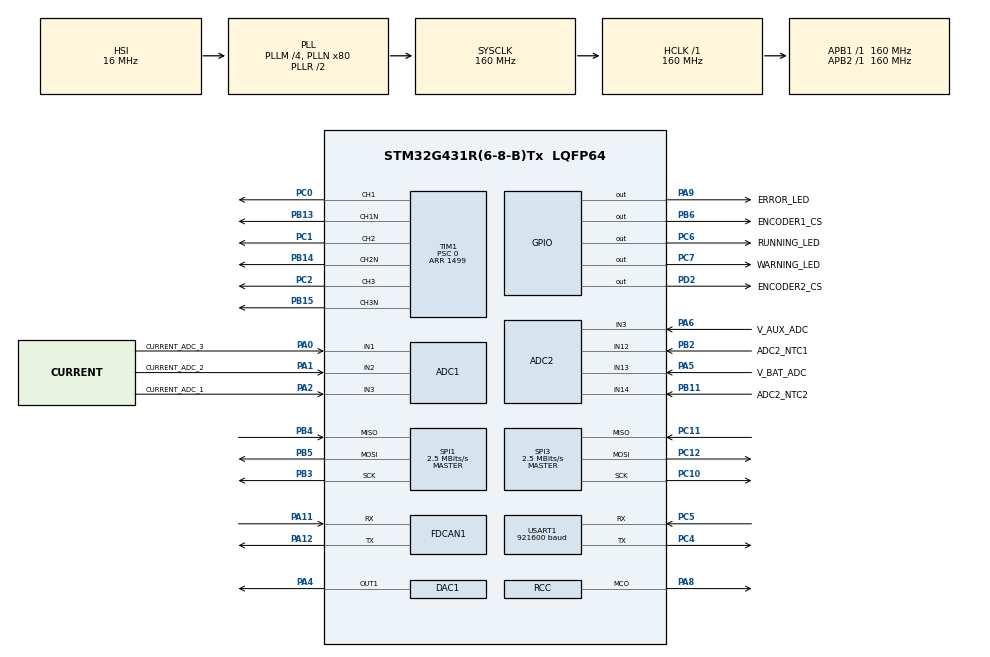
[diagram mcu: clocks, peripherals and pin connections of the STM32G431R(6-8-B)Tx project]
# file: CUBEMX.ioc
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ADC1.Channel-0\#ChannelRegularConversion=ADC_CHANNEL_1
ADC1.Channel-1\#ChannelRegularConversion=ADC_CHANNEL_2
ADC1.Channel-2\#ChannelRegularConversion=ADC_CHANNEL_3
ADC1.Channel-3\#ChannelRegularConversion=ADC_CHANNEL_VREFINT
ADC1.ClockPrescaler=ADC_CLOCK_SYNC_PCLK_DIV4
ADC1.ContinuousConvMode=ENABLE
ADC1.DMAContinuousRequests=ENABLE
ADC1.EOCSelection=ADC_EOC_SEQ_CONV
ADC1.NbrOfConversion=4
ADC1.NbrOfConversionFlag=1
ADC1.OffsetNumber-0\#ChannelRegularConversion=ADC_OFFSET_NONE
ADC1.OffsetNumber-1\#ChannelRegularConversion=ADC_OFFSET_NONE
ADC1.OffsetNumber-2\#ChannelRegularConversion=ADC_OFFSET_NONE
ADC1.OffsetNumber-3\#ChannelRegularConversion=ADC_OFFSET_NONE
ADC1.Overrun=ADC_OVR_DATA_OVERWRITTEN
ADC1.OversamplingMode=ENABLE
ADC1.Rank-0\#ChannelRegularConversion=1
ADC1.Rank-1\#ChannelRegularConversion=2
ADC1.Rank-2\#ChannelRegularConversion=3
ADC1.Rank-3\#ChannelRegularConversion=4
ADC1.Ratio=ADC_OVERSAMPLING_RATIO_16
ADC1.SamplingTime-0\#ChannelRegularConversion=ADC_SAMPLETIME_24CYCLES_5
ADC1.SamplingTime-1\#ChannelRegularConversion=ADC_SAMPLETIME_24CYCLES_5
ADC1.SamplingTime-2\#ChannelRegularConversion=ADC_SAMPLETIME_24CYCLES_5
ADC1.SamplingTime-3\#ChannelRegularConversion=ADC_SAMPLETIME_24CYCLES_5
ADC1.master=1
ADC2.Channel-2\#ChannelRegularConversion=ADC_CHANNEL_12
ADC2.Channel-3\#ChannelRegularConversion=ADC_CHANNEL_14
ADC2.Channel-4\#ChannelRegularConversion=ADC_CHANNEL_3
ADC2.Channel-5\#ChannelRegularConversion=ADC_CHANNEL_13
ADC2.ClockPrescaler=ADC_CLOCK_SYNC_PCLK_DIV4
ADC2.ContinuousConvMode=ENABLE
ADC2.DMAContinuousRequests=ENABLE
ADC2.NbrOfConversion=4
ADC2.NbrOfConversionFlag=1
ADC2.OffsetNumber-2\#ChannelRegularConversion=ADC_OFFSET_NONE
ADC2.OffsetNumber-3\#ChannelRegularConversion=ADC_OFFSET_NONE
ADC2.OffsetNumber-4\#ChannelRegularConversion=ADC_OFFSET_NONE
ADC2.OffsetNumber-5\#ChannelRegularConversion=ADC_OFFSET_NONE
ADC2.Overrun=ADC_OVR_DATA_OVERWRITTEN
ADC2.OversamplingMode=ENABLE
ADC2.Rank-2\#ChannelRegularConversion=1
ADC2.Rank-3\#ChannelRegularConversion=2
ADC2.Rank-4\#ChannelRegularConversion=3
ADC2.Rank-5\#ChannelRegularConversion=4
ADC2.Ratio=ADC_OVERSAMPLING_RATIO_16
ADC2.SamplingTime-2\#ChannelRegularConversion=ADC_SAMPLETIME_640CYCLES_5
ADC2.SamplingTime-3\#ChannelRegularConversion=ADC_SAMPLETIME_2CYCLES_5
ADC2.SamplingTime-4\#ChannelRegularConversion=ADC_SAMPLETIME_2CYCLES_5
ADC2.SamplingTime-5\#ChannelRegularConversion=ADC_SAMPLETIME_2CYCLES_5
DAC1.DAC_HighFrequency_OUT1-DAC_OUT1=DAC_HIGH_FREQUENCY_INTERFACE_MODE_DISABLE
DAC1.DAC_Trigger_OUT1-DAC_OUT1=DAC_TRIGGER_NONE
Dma.ADC1.0.Direction=DMA_PERIPH_TO_MEMORY
Dma.ADC1.0.EventEnable=DISABLE
Dma.ADC1.0.Instance=DMA1_Channel1
Dma.ADC1.0.MemDataAlignment=DMA_MDATAALIGN_WORD
Dma.ADC1.0.MemInc=DMA_MINC_ENABLE
Dma.ADC1.0.Mode=DMA_CIRCULAR
Dma.ADC1.0.PeriphDataAlignment=DMA_PDATAALIGN_WORD
Dma.ADC1.0.PeriphInc=DMA_PINC_DISABLE
Dma.ADC1.0.Polarity=HAL_DMAMUX_REQ_GEN_RISING
Dma.ADC1.0.Priority=DMA_PRIORITY_LOW
Dma.ADC1.0.RequestNumber=1
Dma.ADC1.0.SignalID=NONE
Dma.ADC1.0.SyncEnable=DISABLE
Dma.ADC1.0.SyncPolarity=HAL_DMAMUX_SYNC_NO_EVENT
Dma.ADC1.0.SyncRequestNumber=1
Dma.ADC1.0.SyncSignalID=NONE
Dma.ADC2.1.Direction=DMA_PERIPH_TO_MEMORY
Dma.ADC2.1.EventEnable=DISABLE
Dma.ADC2.1.Instance=DMA1_Channel2
Dma.ADC2.1.MemDataAlignment=DMA_MDATAALIGN_WORD
Dma.ADC2.1.MemInc=DMA_MINC_ENABLE
Dma.ADC2.1.Mode=DMA_CIRCULAR
Dma.ADC2.1.PeriphDataAlignment=DMA_PDATAALIGN_WORD
Dma.ADC2.1.PeriphInc=DMA_PINC_DISABLE
Dma.ADC2.1.Polarity=HAL_DMAMUX_REQ_GEN_RISING
Dma.ADC2.1.Priority=DMA_PRIORITY_LOW
Dma.ADC2.1.RequestNumber=1
Dma.ADC2.1.SignalID=NONE
Dma.ADC2.1.SyncEnable=DISABLE
Dma.ADC2.1.SyncPolarity=HAL_DMAMUX_SYNC_NO_EVENT
Dma.ADC2.1.SyncRequestNumber=1
Dma.ADC2.1.SyncSignalID=NONE
Dma.Request0=ADC1
Dma.Request1=ADC2
Dma.Request2=SPI1_RX
Dma.Request3=SPI1_TX
Dma.Request4=SPI3_RX
Dma.Request5=SPI3_TX
Dma.Request6=USART1_TX
Dma.SPI1_RX.2.Direction=DMA_PERIPH_TO_MEMORY
Dma.SPI1_RX.2.EventEnable=DISABLE
Dma.SPI1_RX.2.Instance=DMA1_Channel3
Dma.SPI1_RX.2.MemDataAlignment=DMA_MDATAALIGN_BYTE
Dma.SPI1_RX.2.MemInc=DMA_MINC_ENABLE
Dma.SPI1_RX.2.Mode=DMA_NORMAL
Dma.SPI1_RX.2.PeriphDataAlignment=DMA_PDATAALIGN_BYTE
Dma.SPI1_RX.2.PeriphInc=DMA_PINC_DISABLE
Dma.SPI1_RX.2.Polarity=HAL_DMAMUX_REQ_GEN_RISING
Dma.SPI1_RX.2.Priority=DMA_PRIORITY_LOW
Dma.SPI1_RX.2.RequestNumber=1
Dma.SPI1_RX.2.SignalID=NONE
Dma.SPI1_RX.2.SyncEnable=DISABLE
Dma.SPI1_RX.2.SyncPolarity=HAL_DMAMUX_SYNC_NO_EVENT
Dma.SPI1_RX.2.SyncRequestNumber=1
Dma.SPI1_RX.2.SyncSignalID=NONE
Dma.SPI1_TX.3.Direction=DMA_MEMORY_TO_PERIPH
Dma.SPI1_TX.3.EventEnable=DISABLE
Dma.SPI1_TX.3.Instance=DMA1_Channel4
Dma.SPI1_TX.3.MemDataAlignment=DMA_MDATAALIGN_BYTE
Dma.SPI1_TX.3.MemInc=DMA_MINC_ENABLE
Dma.SPI1_TX.3.Mode=DMA_NORMAL
Dma.SPI1_TX.3.PeriphDataAlignment=DMA_PDATAALIGN_BYTE
Dma.SPI1_TX.3.PeriphInc=DMA_PINC_DISABLE
Dma.SPI1_TX.3.Polarity=HAL_DMAMUX_REQ_GEN_RISING
Dma.SPI1_TX.3.Priority=DMA_PRIORITY_LOW
Dma.SPI1_TX.3.RequestNumber=1
Dma.SPI1_TX.3.SignalID=NONE
Dma.SPI1_TX.3.SyncEnable=DISABLE
Dma.SPI1_TX.3.SyncPolarity=HAL_DMAMUX_SYNC_NO_EVENT
Dma.SPI1_TX.3.SyncRequestNumber=1
Dma.SPI1_TX.3.SyncSignalID=NONE
Dma.SPI3_RX.4.Direction=DMA_PERIPH_TO_MEMORY
Dma.SPI3_RX.4.EventEnable=DISABLE
Dma.SPI3_RX.4.Instance=DMA2_Channel1
Dma.SPI3_RX.4.MemDataAlignment=DMA_MDATAALIGN_BYTE
Dma.SPI3_RX.4.MemInc=DMA_MINC_ENABLE
Dma.SPI3_RX.4.Mode=DMA_NORMAL
Dma.SPI3_RX.4.PeriphDataAlignment=DMA_PDATAALIGN_BYTE
Dma.SPI3_RX.4.PeriphInc=DMA_PINC_DISABLE
Dma.SPI3_RX.4.Polarity=HAL_DMAMUX_REQ_GEN_RISING
Dma.SPI3_RX.4.Priority=DMA_PRIORITY_LOW
Dma.SPI3_RX.4.RequestNumber=1
Dma.SPI3_RX.4.SignalID=NONE
Dma.SPI3_RX.4.SyncEnable=DISABLE
Dma.SPI3_RX.4.SyncPolarity=HAL_DMAMUX_SYNC_NO_EVENT
Dma.SPI3_RX.4.SyncRequestNumber=1
Dma.SPI3_RX.4.SyncSignalID=NONE
Dma.SPI3_TX.5.Direction=DMA_MEMORY_TO_PERIPH
Dma.SPI3_TX.5.EventEnable=DISABLE
Dma.SPI3_TX.5.Instance=DMA2_Channel2
Dma.SPI3_TX.5.MemDataAlignment=DMA_MDATAALIGN_BYTE
Dma.SPI3_TX.5.MemInc=DMA_MINC_ENABLE
Dma.SPI3_TX.5.Mode=DMA_NORMAL
Dma.SPI3_TX.5.PeriphDataAlignment=DMA_PDATAALIGN_BYTE
Dma.SPI3_TX.5.PeriphInc=DMA_PINC_DISABLE
Dma.SPI3_TX.5.Polarity=HAL_DMAMUX_REQ_GEN_RISING
Dma.SPI3_TX.5.Priority=DMA_PRIORITY_LOW
Dma.SPI3_TX.5.RequestNumber=1
Dma.SPI3_TX.5.SignalID=NONE
Dma.SPI3_TX.5.SyncEnable=DISABLE
Dma.SPI3_TX.5.SyncPolarity=HAL_DMAMUX_SYNC_NO_EVENT
Dma.SPI3_TX.5.SyncRequestNumber=1
Dma.SPI3_TX.5.SyncSignalID=NONE
Dma.USART1_TX.6.Direction=DMA_MEMORY_TO_PERIPH
Dma.USART1_TX.6.EventEnable=DISABLE
Dma.USART1_TX.6.Instance=DMA2_Channel3
Dma.USART1_TX.6.MemDataAlignment=DMA_MDATAALIGN_BYTE
Dma.USART1_TX.6.MemInc=DMA_MINC_ENABLE
Dma.USART1_TX.6.Mode=DMA_NORMAL
Dma.USART1_TX.6.PeriphDataAlignment=DMA_PDATAALIGN_BYTE
Dma.USART1_TX.6.PeriphInc=DMA_PINC_DISABLE
Dma.USART1_TX.6.Polarity=HAL_DMAMUX_REQ_GEN_RISING
Dma.USART1_TX.6.Priority=DMA_PRIORITY_LOW
Dma.USART1_TX.6.RequestNumber=1
Dma.USART1_TX.6.SignalID=NONE
Dma.USART1_TX.6.SyncEnable=DISABLE
Dma.USART1_TX.6.SyncPolarity=HAL_DMAMUX_SYNC_NO_EVENT
Dma.USART1_TX.6.SyncRequestNumber=1
Dma.USART1_TX.6.SyncSignalID=NONE
FDCAN1.AutoRetransmission=DISABLE
FDCAN1.CalculateBaudRateNominal=1000000
FDCAN1.CalculateTimeBitNominal=1000
FDCAN1.CalculateTimeQuantumNominal=50.0
FDCAN1.ClockDivider=FDCAN_CLOCK_DIV1
FDCAN1.DataPrescaler=2
FDCAN1.DataSyncJumpWidth=1
FDCAN1.DataTimeSeg1=7
FDCAN1.DataTimeSeg2=2
FDCAN1.FrameFormat=FDCAN_FRAME_FD_BRS
FDCAN1.Mode=FDCAN_MODE_NORMAL
FDCAN1.NominalPrescaler=2
FDCAN1.NominalSyncJumpWidth=1
FDCAN1.NominalTimeSeg1=13
FDCAN1.NominalTimeSeg2=6
Mcu.Family=STM32G4
Mcu.Name=STM32G431R(6-8-B)Tx
Mcu.Package=LQFP64
NVIC.ADC1_2_IRQn=true\:0\:0\:true\:false\:true\:true\:true\:true
NVIC.DMA1_Channel1_IRQn=true\:0\:0\:true\:false\:true\:false\:true\:true
NVIC.DMA1_Channel2_IRQn=true\:0\:0\:true\:false\:true\:false\:true\:true
NVIC.DMA1_Channel3_IRQn=true\:0\:0\:true\:false\:true\:false\:true\:true
NVIC.DMA1_Channel4_IRQn=true\:0\:0\:true\:false\:true\:false\:true\:true
NVIC.DMA2_Channel1_IRQn=true\:0\:0\:true\:false\:true\:false\:true\:true
NVIC.DMA2_Channel2_IRQn=true\:0\:0\:true\:false\:true\:false\:true\:true
NVIC.DMA2_Channel3_IRQn=true\:0\:0\:true\:false\:true\:false\:true\:true
NVIC.FDCAN1_IT0_IRQn=true\:0\:0\:true\:false\:true\:true\:true\:true
NVIC.PriorityGroup=NVIC_PRIORITYGROUP_4
NVIC.SPI1_IRQn=true\:0\:0\:false\:false\:true\:true\:true\:true
NVIC.SPI3_IRQn=true\:0\:0\:false\:false\:true\:true\:true\:true
NVIC.TIM3_IRQn=true\:0\:0\:false\:false\:true\:true\:true\:true
NVIC.USART1_IRQn=true\:0\:0\:false\:false\:true\:true\:true\:true
PA0.GPIO_Label=CURRENT_ADC_3
PA0.Mode=IN1-Single-Ended
PA0.Signal=ADC1_IN1
PA1.GPIO_Label=CURRENT_ADC_2
PA1.Mode=IN2-Single-Ended
PA1.Signal=ADC1_IN2
PA11.Mode=FDCAN_Activate
PA11.Signal=FDCAN1_RX
PA12.Mode=FDCAN_Activate
PA12.Signal=FDCAN1_TX
PA13.Mode=Serial_Wire
PA13.Signal=SYS_JTMS-SWDIO
PA14.Mode=Serial_Wire
PA14.Signal=SYS_JTCK-SWCLK
PA2.GPIO_Label=CURRENT_ADC_1
PA2.Mode=IN3-Single-Ended
PA2.Signal=ADC1_IN3
PA4.Signal=COMP_DAC11_group
PA5.GPIO_Label=V_BAT_ADC
PA5.Mode=IN13-Single-Ended
PA5.Signal=ADC2_IN13
PA6.GPIO_Label=V_AUX_ADC
PA6.Mode=IN3-Single-Ended
PA6.Signal=ADC2_IN3
PA8.Mode=Clock-out
PA8.Signal=RCC_MCO
PA9.GPIO_Label=ERROR_LED
PA9.Signal=GPIO_Output
PB11.GPIO_Label=ADC2_NTC2
PB11.Mode=IN14-Single-Ended
PB11.Signal=ADC2_IN14
PB13.Mode=PWM Generation1 CH1 CH1N
PB13.Signal=TIM1_CH1N
PB14.Mode=PWM Generation2 CH2 CH2N
PB14.Signal=TIM1_CH2N
PB15.Mode=PWM Generation3 CH3 CH3N
PB15.Signal=TIM1_CH3N
PB2.GPIO_Label=ADC2_NTC1
PB2.Mode=IN12-Single-Ended
PB2.Signal=ADC2_IN12
PB3.Mode=Full_Duplex_Master
PB3.Signal=SPI1_SCK
PB4.Mode=Full_Duplex_Master
PB4.Signal=SPI1_MISO
PB5.Mode=Full_Duplex_Master
PB5.Signal=SPI1_MOSI
PB6.GPIO_Label=ENCODER1_CS
PB6.Signal=GPIO_Output
PC0.Signal=S_TIM1_CH1
PC1.Signal=S_TIM1_CH2
PC10.Mode=Full_Duplex_Master
PC10.Signal=SPI3_SCK
PC11.Mode=Full_Duplex_Master
PC11.Signal=SPI3_MISO
PC12.Mode=Full_Duplex_Master
PC12.Signal=SPI3_MOSI
PC2.Signal=S_TIM1_CH3
PC4.Mode=Asynchronous
PC4.Signal=USART1_TX
PC5.Mode=Asynchronous
PC5.Signal=USART1_RX
PC6.GPIO_Label=RUNNING_LED
PC6.Signal=GPIO_Output
PC7.GPIO_Label=WARNING_LED
PC7.Signal=GPIO_Output
PD2.GPIO_Label=ENCODER2_CS
PD2.Signal=GPIO_Output
PF0-OSC_IN.Mode=HSE-External-Oscillator
PF0-OSC_IN.Signal=RCC_OSC_IN
PF1-OSC_OUT.Mode=HSE-External-Oscillator
PF1-OSC_OUT.Signal=RCC_OSC_OUT
ProjectManager.HeapSize=0x200
ProjectManager.StackSize=0x400
ProjectManager.TargetToolchain=STM32CubeIDE
RCC.ADC12Freq_Value=160000000
RCC.AHBFreq_Value=160000000
RCC.APB1Freq_Value=160000000
RCC.APB1TimFreq_Value=160000000
RCC.APB2Freq_Value=160000000
RCC.APB2TimFreq_Value=160000000
RCC.CortexFreq_Value=160000000
RCC.EXTERNAL_CLOCK_VALUE=12288000
RCC.FDCANCLockSelection=RCC_FDCANCLKSOURCE_PLL
RCC.HCLKFreq_Value=160000000
RCC.HSE_VALUE=16000000
RCC.HSI48_VALUE=48000000
RCC.HSI_VALUE=16000000
RCC.LSE_VALUE=32768
RCC.PLLM=RCC_PLLM_DIV4
RCC.PLLN=80
RCC.PLLQ=RCC_PLLQ_DIV8
RCC.RCC_MCODiv=RCC_MCODIV_16
RCC.SYSCLKFreq_VALUE=160000000
RCC.SYSCLKSource=RCC_SYSCLKSOURCE_PLLCLK
RCC.USBFreq_Value=40000000
RCC.VCOOutputFreq_Value=320000000
SH.COMP_DAC11_group.0=DAC1_OUT1,DAC_OUT1
SH.S_TIM1_CH1.0=TIM1_CH1,PWM Generation1 CH1 CH1N
SH.S_TIM1_CH2.0=TIM1_CH2,PWM Generation2 CH2 CH2N
SH.S_TIM1_CH3.0=TIM1_CH3,PWM Generation3 CH3 CH3N
SPI1.BaudRatePrescaler=SPI_BAUDRATEPRESCALER_64
SPI1.CLKPhase=SPI_PHASE_2EDGE
SPI1.CRCCalculation=SPI_CRCCALCULATION_DISABLE
SPI1.CalculateBaudRate=2.5 MBits/s
SPI1.DataSize=SPI_DATASIZE_8BIT
SPI1.Direction=SPI_DIRECTION_2LINES
SPI1.Mode=SPI_MODE_MASTER
SPI1.VirtualType=VM_MASTER
SPI3.BaudRatePrescaler=SPI_BAUDRATEPRESCALER_64
SPI3.CLKPhase=SPI_PHASE_2EDGE
SPI3.CalculateBaudRate=2.5 MBits/s
SPI3.DataSize=SPI_DATASIZE_8BIT
SPI3.Direction=SPI_DIRECTION_2LINES
SPI3.Mode=SPI_MODE_MASTER
SPI3.VirtualType=VM_MASTER
TIM1.AsymmetricalDeadTime=ENABLE
TIM1.AutoReloadPreload=TIM_AUTORELOAD_PRELOAD_ENABLE
TIM1.AutomaticOutput=TIM_AUTOMATICOUTPUT_DISABLE
TIM1.Break2Polarity=TIM_BREAK2POLARITY_HIGH
TIM1.BreakPolarity=TIM_BREAKPOLARITY_HIGH
TIM1.Channel-PWM\ Generation1\ CH1\ CH1N=TIM_CHANNEL_1
TIM1.Channel-PWM\ Generation2\ CH2\ CH2N=TIM_CHANNEL_2
TIM1.Channel-PWM\ Generation3\ CH3\ CH3N=TIM_CHANNEL_3
TIM1.CounterMode=TIM_COUNTERMODE_CENTERALIGNED1
TIM1.DeadTime=25
TIM1.DeadTimePreload=ENABLE
TIM1.FallingDeadTime=25
TIM1.OCFastMode_PWM-PWM\ Generation1\ CH1\ CH1N=TIM_OCFAST_ENABLE
TIM1.OCFastMode_PWM-PWM\ Generation2\ CH2\ CH2N=TIM_OCFAST_ENABLE
TIM1.OCFastMode_PWM-PWM\ Generation3\ CH3\ CH3N=TIM_OCFAST_ENABLE
TIM1.OCNPolarity_1=TIM_OCNPOLARITY_LOW
TIM1.OCNPolarity_2=TIM_OCNPOLARITY_LOW
TIM1.OCNPolarity_3=TIM_OCNPOLARITY_LOW
TIM1.OCPolarity_1=TIM_OCPOLARITY_LOW
TIM1.OCPolarity_2=TIM_OCPOLARITY_LOW
TIM1.OCPolarity_3=TIM_OCPOLARITY_LOW
TIM1.PeriodNoDither=1499
TIM1.Prescaler=0
TIM1.TIM_MasterOutputTrigger2=TIM_TRGO2_RESET
TIM3.AutoReloadPreload=TIM_AUTORELOAD_PRELOAD_ENABLE
TIM3.PeriodNoDither=3999
TIM3.Prescaler=3
USART1.BaudRate=921600
USART1.VirtualMode-Asynchronous=VM_ASYNC
VP_ADC1_Vref_Input.Mode=IN-Vrefint
VP_CORDIC_VS_CORDIC.Mode=CORDIC_Activate
VP_FMAC_VS_FMAC.Mode=FMAC_Activate
VP_SYS_VS_DBSignals.Mode=DisableDeadBatterySignals
VP_TIM1_VS_ClockSourceINT.Mode=Internal
VP_TIM3_VS_ClockSourceINT.Mode=Internal
board=custom

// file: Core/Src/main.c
/* USER CODE BEGIN Header */
/**
  ******************************************************************************
  * @file           : main.c
  * @brief          : Main program body
  ******************************************************************************
  * @attention
  *
  * Copyright (c) 2023 STMicroelectronics.
  * All rights reserved.
  *
  * This software is licensed under terms that can be found in the LICENSE file
  * in the root directory of this software component.
  * If no LICENSE file comes with this software, it is provided AS-IS.
  *
  ******************************************************************************
  */
/* USER CODE END Header */
#include "main.h"
#include "adc.h"
#include "cordic.h"
#include "dac.h"
#include "dma.h"
#include "fdcan.h"
#include "fmac.h"
#include "spi.h"
#include "tim.h"
#include "usart.h"
#include "gpio.h"

/* USER CODE BEGIN Includes */
#include "BLDC_FOC.h"
/* USER CODE END Includes */

void SystemClock_Config(void);

int main(void)
{

  /* MCU Configuration--------------------------------------------------------*/

  /* Reset of all peripherals, Initializes the Flash interface and the Systick. */
  HAL_Init();

  /* Configure the system clock */
  SystemClock_Config();

  /* Initialize all configured peripherals */
  MX_GPIO_Init();
  MX_DMA_Init();
  MX_FDCAN1_Init();
  MX_SPI1_Init();
  MX_SPI3_Init();
  MX_TIM1_Init();
  MX_ADC1_Init();
  MX_ADC2_Init();
  MX_DAC1_Init();
  MX_USART1_UART_Init();
  MX_TIM3_Init();
  MX_FMAC_Init();
  MX_CORDIC_Init();

  /* Infinite loop */
  /* USER CODE BEGIN WHILE */
  while (1)
  {
	BLDC_main();
    /* USER CODE END WHILE */

  }
}

void SystemClock_Config(void)
{
  RCC_OscInitTypeDef RCC_OscInitStruct = {0};
  RCC_ClkInitTypeDef RCC_ClkInitStruct = {0};

  /** Configure the main internal regulator output voltage
  */
  HAL_PWREx_ControlVoltageScaling(PWR_REGULATOR_VOLTAGE_SCALE1_BOOST);

  /** Initializes the RCC Oscillators according to the specified parameters
  * in the RCC_OscInitTypeDef structure.
  */
  RCC_OscInitStruct.OscillatorType = RCC_OSCILLATORTYPE_HSI;
  RCC_OscInitStruct.HSIState = RCC_HSI_ON;
  RCC_OscInitStruct.HSICalibrationValue = RCC_HSICALIBRATION_DEFAULT;
  RCC_OscInitStruct.PLL.PLLState = RCC_PLL_ON;
  RCC_OscInitStruct.PLL.PLLSource = RCC_PLLSOURCE_HSI;
  RCC_OscInitStruct.PLL.PLLM = RCC_PLLM_DIV4;
  RCC_OscInitStruct.PLL.PLLN = 80;
  RCC_OscInitStruct.PLL.PLLP = RCC_PLLP_DIV2;
  RCC_OscInitStruct.PLL.PLLQ = RCC_PLLQ_DIV8;
  RCC_OscInitStruct.PLL.PLLR = RCC_PLLR_DIV2;
  if (HAL_RCC_OscConfig(&RCC_OscInitStruct) != HAL_OK)
  {
    Error_Handler();
  }

  /** Initializes the CPU, AHB and APB buses clocks
  */
  RCC_ClkInitStruct.ClockType = RCC_CLOCKTYPE_HCLK|RCC_CLOCKTYPE_SYSCLK
                              |RCC_CLOCKTYPE_PCLK1|RCC_CLOCKTYPE_PCLK2;
  RCC_ClkInitStruct.SYSCLKSource = RCC_SYSCLKSOURCE_PLLCLK;
  RCC_ClkInitStruct.AHBCLKDivider = RCC_SYSCLK_DIV1;
  RCC_ClkInitStruct.APB1CLKDivider = RCC_HCLK_DIV1;
  RCC_ClkInitStruct.APB2CLKDivider = RCC_HCLK_DIV1;

  if (HAL_RCC_ClockConfig(&RCC_ClkInitStruct, FLASH_LATENCY_4) != HAL_OK)
  {
    Error_Handler();
  }
  HAL_RCC_MCOConfig(RCC_MCO1, RCC_MCO1SOURCE_HSI, RCC_MCODIV_16);
}

void Error_Handler(void)
{
  __disable_irq();
  while (1)
  {
  }
}
